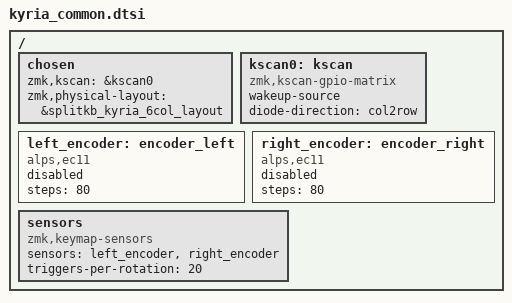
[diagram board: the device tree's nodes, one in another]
#include <dt-bindings/zmk/matrix_transform.h>
#include "kyria-layouts.dtsi"

/ {
    chosen {
        zmk,kscan = &kscan0;
        zmk,physical-layout = &splitkb_kyria_6col_layout;
    };

    kscan0: kscan {
        compatible = "zmk,kscan-gpio-matrix";
        wakeup-source;

        diode-direction = "col2row";
    };

    left_encoder: encoder_left {
        compatible = "alps,ec11";
        steps = <80>;
        status = "disabled";
    };

    right_encoder: encoder_right {
        compatible = "alps,ec11";
        steps = <80>;
        status = "disabled";
    };

    sensors: sensors {
        compatible = "zmk,keymap-sensors";
        sensors = <&left_encoder &right_encoder>;
        triggers-per-rotation = <20>;
    }; 
};

